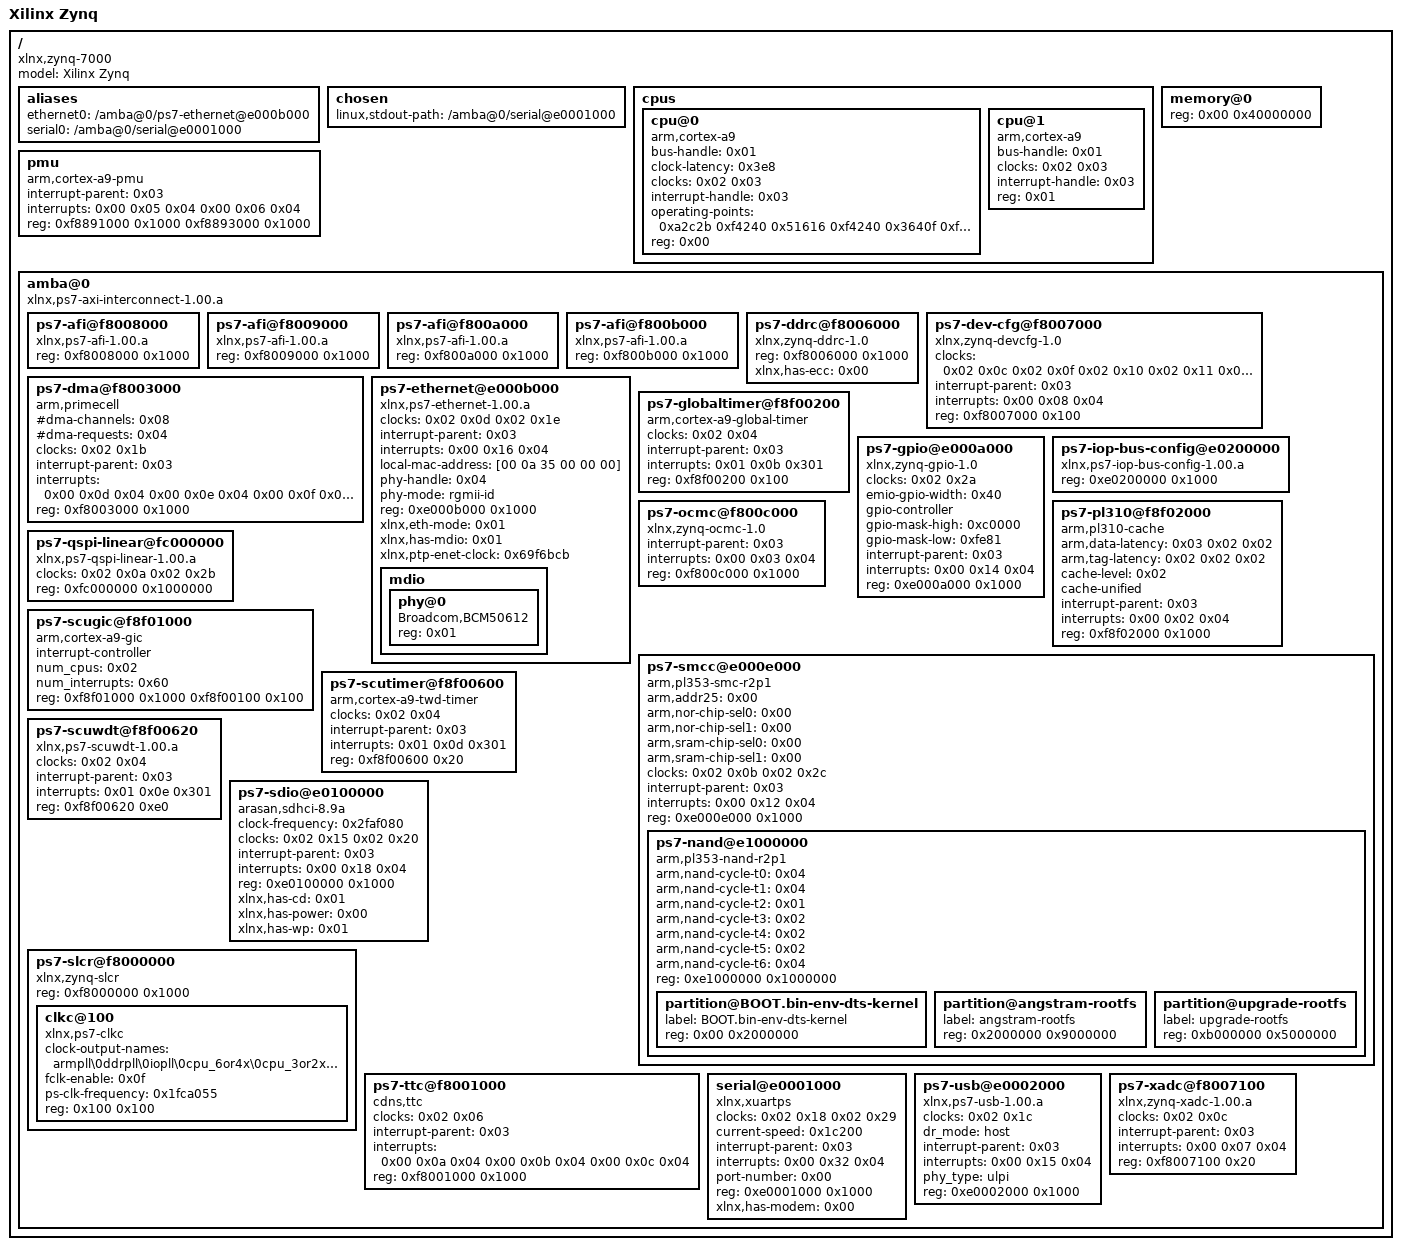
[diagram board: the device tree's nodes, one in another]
/dts-v1/;

/ {
	#address-cells = <0x01>;
	#size-cells = <0x01>;
	compatible = "xlnx,zynq-7000";
	model = "Xilinx Zynq";

	aliases {
		ethernet0 = "/amba@0/ps7-ethernet@e000b000";
		serial0 = "/amba@0/serial@e0001000";
	};

	chosen {
		linux,stdout-path = "/amba@0/serial@e0001000";
	};

	cpus {
		#address-cells = <0x01>;
		#size-cells = <0x00>;

		cpu@0 {
			bus-handle = <0x01>;
			clock-latency = <0x3e8>;
			clocks = <0x02 0x03>;
			compatible = "arm,cortex-a9";
			device_type = "cpu";
			interrupt-handle = <0x03>;
			operating-points = <0xa2c2b 0xf4240 0x51616 0xf4240 0x3640f 0xf4240>;
			reg = <0x00>;
		};

		cpu@1 {
			bus-handle = <0x01>;
			clocks = <0x02 0x03>;
			compatible = "arm,cortex-a9";
			device_type = "cpu";
			interrupt-handle = <0x03>;
			reg = <0x01>;
		};
	};

	pmu {
		compatible = "arm,cortex-a9-pmu";
		interrupt-parent = <0x03>;
		interrupts = <0x00 0x05 0x04 0x00 0x06 0x04>;
		reg = <0xf8891000 0x1000 0xf8893000 0x1000>;
		reg-names = "cpu0\0cpu1";
	};

	memory@0 {
		device_type = "memory";
		reg = <0x00 0x40000000>;
	};

	amba@0 {
		#address-cells = <0x01>;
		#size-cells = <0x01>;
		compatible = "xlnx,ps7-axi-interconnect-1.00.a\0simple-bus";
		ranges;
		linux,phandle = <0x01>;
		phandle = <0x01>;

		ps7-afi@f8008000 {
			compatible = "xlnx,ps7-afi-1.00.a";
			reg = <0xf8008000 0x1000>;
		};

		ps7-afi@f8009000 {
			compatible = "xlnx,ps7-afi-1.00.a";
			reg = <0xf8009000 0x1000>;
		};

		ps7-afi@f800a000 {
			compatible = "xlnx,ps7-afi-1.00.a";
			reg = <0xf800a000 0x1000>;
		};

		ps7-afi@f800b000 {
			compatible = "xlnx,ps7-afi-1.00.a";
			reg = <0xf800b000 0x1000>;
		};

		ps7-ddrc@f8006000 {
			compatible = "xlnx,zynq-ddrc-1.0";
			reg = <0xf8006000 0x1000>;
			xlnx,has-ecc = <0x00>;
		};

		ps7-dev-cfg@f8007000 {
			clock-names = "ref_clk\0fclk0\0fclk1\0fclk2\0fclk3";
			clocks = <0x02 0x0c 0x02 0x0f 0x02 0x10 0x02 0x11 0x02 0x12>;
			compatible = "xlnx,zynq-devcfg-1.0";
			interrupt-parent = <0x03>;
			interrupts = <0x00 0x08 0x04>;
			reg = <0xf8007000 0x100>;
		};

		ps7-dma@f8003000 {
			#dma-cells = <0x01>;
			#dma-channels = <0x08>;
			#dma-requests = <0x04>;
			clock-names = "apb_pclk";
			clocks = <0x02 0x1b>;
			compatible = "arm,primecell\0arm,pl330";
			interrupt-names = "abort\0dma0\0dma1\0dma2\0dma3\0dma4\0dma5\0dma6\0dma7";
			interrupt-parent = <0x03>;
			interrupts = <0x00 0x0d 0x04 0x00 0x0e 0x04 0x00 0x0f 0x04 0x00 0x10 0x04 0x00 0x11 0x04 0x00 0x28 0x04 0x00 0x29 0x04 0x00 0x2a 0x04 0x00 0x2b 0x04>;
			reg = <0xf8003000 0x1000>;
		};

		ps7-ethernet@e000b000 {
			#address-cells = <0x01>;
			#size-cells = <0x00>;
			clock-names = "ref_clk\0aper_clk";
			clocks = <0x02 0x0d 0x02 0x1e>;
			compatible = "xlnx,ps7-ethernet-1.00.a";
			interrupt-parent = <0x03>;
			interrupts = <0x00 0x16 0x04>;
			local-mac-address = [00 0a 35 00 00 00];
			phy-handle = <0x04>;
			phy-mode = "rgmii-id";
			reg = <0xe000b000 0x1000>;
			xlnx,eth-mode = <0x01>;
			xlnx,has-mdio = <0x01>;
			xlnx,ptp-enet-clock = <0x69f6bcb>;

			mdio {
				#address-cells = <0x01>;
				#size-cells = <0x00>;

				phy@0 {
					compatible = "Broadcom,BCM50612";
					device_type = "ethernet-phy";
					reg = <0x01>;
					linux,phandle = <0x04>;
					phandle = <0x04>;
				};
			};
		};

		ps7-globaltimer@f8f00200 {
			clocks = <0x02 0x04>;
			compatible = "arm,cortex-a9-global-timer";
			interrupt-parent = <0x03>;
			interrupts = <0x01 0x0b 0x301>;
			reg = <0xf8f00200 0x100>;
		};

		ps7-gpio@e000a000 {
			#gpio-cells = <0x02>;
			clocks = <0x02 0x2a>;
			compatible = "xlnx,zynq-gpio-1.0";
			emio-gpio-width = <0x40>;
			gpio-controller;
			gpio-mask-high = <0xc0000>;
			gpio-mask-low = <0xfe81>;
			interrupt-parent = <0x03>;
			interrupts = <0x00 0x14 0x04>;
			reg = <0xe000a000 0x1000>;
		};

		ps7-iop-bus-config@e0200000 {
			compatible = "xlnx,ps7-iop-bus-config-1.00.a";
			reg = <0xe0200000 0x1000>;
		};

		ps7-ocmc@f800c000 {
			compatible = "xlnx,zynq-ocmc-1.0";
			interrupt-parent = <0x03>;
			interrupts = <0x00 0x03 0x04>;
			reg = <0xf800c000 0x1000>;
		};

		ps7-pl310@f8f02000 {
			arm,data-latency = <0x03 0x02 0x02>;
			arm,tag-latency = <0x02 0x02 0x02>;
			cache-level = <0x02>;
			cache-unified;
			compatible = "arm,pl310-cache";
			interrupt-parent = <0x03>;
			interrupts = <0x00 0x02 0x04>;
			reg = <0xf8f02000 0x1000>;
		};

		ps7-smcc@e000e000 {
			#address-cells = <0x01>;
			#size-cells = <0x01>;
			arm,addr25 = <0x00>;
			arm,nor-chip-sel0 = <0x00>;
			arm,nor-chip-sel1 = <0x00>;
			arm,sram-chip-sel0 = <0x00>;
			arm,sram-chip-sel1 = <0x00>;
			clock-names = "memclk\0aclk";
			clocks = <0x02 0x0b 0x02 0x2c>;
			compatible = "arm,pl353-smc-r2p1";
			interrupt-parent = <0x03>;
			interrupts = <0x00 0x12 0x04>;
			ranges;
			reg = <0xe000e000 0x1000>;

			ps7-nand@e1000000 {
				arm,nand-cycle-t0 = <0x04>;
				arm,nand-cycle-t1 = <0x04>;
				arm,nand-cycle-t2 = <0x01>;
				arm,nand-cycle-t3 = <0x02>;
				arm,nand-cycle-t4 = <0x02>;
				arm,nand-cycle-t5 = <0x02>;
				arm,nand-cycle-t6 = <0x04>;
				compatible = "arm,pl353-nand-r2p1";
				reg = <0xe1000000 0x1000000>;
				#address-cells = <0x01>;
				#size-cells = <0x01>;

				partition@BOOT.bin-env-dts-kernel {
					label = "BOOT.bin-env-dts-kernel";
					reg = <0x00 0x2000000>;
				};

				partition@angstram-rootfs {
					label = "angstram-rootfs";
					reg = <0x2000000 0x9000000>;
				};

				partition@upgrade-rootfs {
					label = "upgrade-rootfs";
					reg = <0xb000000 0x5000000>;
				};
			};
		};

		ps7-qspi-linear@fc000000 {
			clock-names = "ref_clk\0aper_clk";
			clocks = <0x02 0x0a 0x02 0x2b>;
			compatible = "xlnx,ps7-qspi-linear-1.00.a";
			reg = <0xfc000000 0x1000000>;
		};

		ps7-scugic@f8f01000 {
			#address-cells = <0x02>;
			#interrupt-cells = <0x03>;
			#size-cells = <0x01>;
			compatible = "arm,cortex-a9-gic\0arm,gic";
			interrupt-controller;
			num_cpus = <0x02>;
			num_interrupts = <0x60>;
			reg = <0xf8f01000 0x1000 0xf8f00100 0x100>;
			linux,phandle = <0x03>;
			phandle = <0x03>;
		};

		ps7-scutimer@f8f00600 {
			clocks = <0x02 0x04>;
			compatible = "arm,cortex-a9-twd-timer";
			interrupt-parent = <0x03>;
			interrupts = <0x01 0x0d 0x301>;
			reg = <0xf8f00600 0x20>;
		};

		ps7-scuwdt@f8f00620 {
			clocks = <0x02 0x04>;
			compatible = "xlnx,ps7-scuwdt-1.00.a";
			device_type = "watchdog";
			interrupt-parent = <0x03>;
			interrupts = <0x01 0x0e 0x301>;
			reg = <0xf8f00620 0xe0>;
		};

		ps7-sdio@e0100000 {
			clock-frequency = <0x2faf080>;
			clock-names = "clk_xin\0clk_ahb";
			clocks = <0x02 0x15 0x02 0x20>;
			compatible = "arasan,sdhci-8.9a";
			interrupt-parent = <0x03>;
			interrupts = <0x00 0x18 0x04>;
			reg = <0xe0100000 0x1000>;
			xlnx,has-cd = <0x01>;
			xlnx,has-power = <0x00>;
			xlnx,has-wp = <0x01>;
		};

		ps7-slcr@f8000000 {
			#address-cells = <0x01>;
			#size-cells = <0x01>;
			compatible = "xlnx,zynq-slcr\0syscon";
			ranges;
			reg = <0xf8000000 0x1000>;

			clkc@100 {
				#clock-cells = <0x01>;
				clock-output-names = "armpll\0ddrpll\0iopll\0cpu_6or4x\0cpu_3or2x\0cpu_2x\0cpu_1x\0ddr2x\0ddr3x\0dci\0lqspi\0smc\0pcap\0gem0\0gem1\0fclk0\0fclk1\0fclk2\0fclk3\0can0\0can1\0sdio0\0sdio1\0uart0\0uart1\0spi0\0spi1\0dma\0usb0_aper\0usb1_aper\0gem0_aper\0gem1_aper\0sdio0_aper\0sdio1_aper\0spi0_aper\0spi1_aper\0can0_aper\0can1_aper\0i2c0_aper\0i2c1_aper\0uart0_aper\0uart1_aper\0gpio_aper\0lqspi_aper\0smc_aper\0swdt\0dbg_trc\0dbg_apb";
				compatible = "xlnx,ps7-clkc";
				fclk-enable = <0x0f>;
				ps-clk-frequency = <0x1fca055>;
				reg = <0x100 0x100>;
				linux,phandle = <0x02>;
				phandle = <0x02>;
			};
		};

		ps7-ttc@f8001000 {
			clocks = <0x02 0x06>;
			compatible = "cdns,ttc";
			interrupt-names = "ttc0\0ttc1\0ttc2";
			interrupt-parent = <0x03>;
			interrupts = <0x00 0x0a 0x04 0x00 0x0b 0x04 0x00 0x0c 0x04>;
			reg = <0xf8001000 0x1000>;
		};

		serial@e0001000 {
			clock-names = "uart_clk\0pclk";
			clocks = <0x02 0x18 0x02 0x29>;
			compatible = "xlnx,xuartps\0cdns,uart-r1p8";
			current-speed = <0x1c200>;
			device_type = "serial";
			interrupt-parent = <0x03>;
			interrupts = <0x00 0x32 0x04>;
			port-number = <0x00>;
			reg = <0xe0001000 0x1000>;
			xlnx,has-modem = <0x00>;
		};

		ps7-usb@e0002000 {
			clocks = <0x02 0x1c>;
			compatible = "xlnx,ps7-usb-1.00.a\0xlnx,zynq-usb-1.00.a";
			dr_mode = "host";
			interrupt-parent = <0x03>;
			interrupts = <0x00 0x15 0x04>;
			phy_type = "ulpi";
			reg = <0xe0002000 0x1000>;
		};

		ps7-xadc@f8007100 {
			clocks = <0x02 0x0c>;
			compatible = "xlnx,zynq-xadc-1.00.a";
			interrupt-parent = <0x03>;
			interrupts = <0x00 0x07 0x04>;
			reg = <0xf8007100 0x20>;
		};
	};
};
